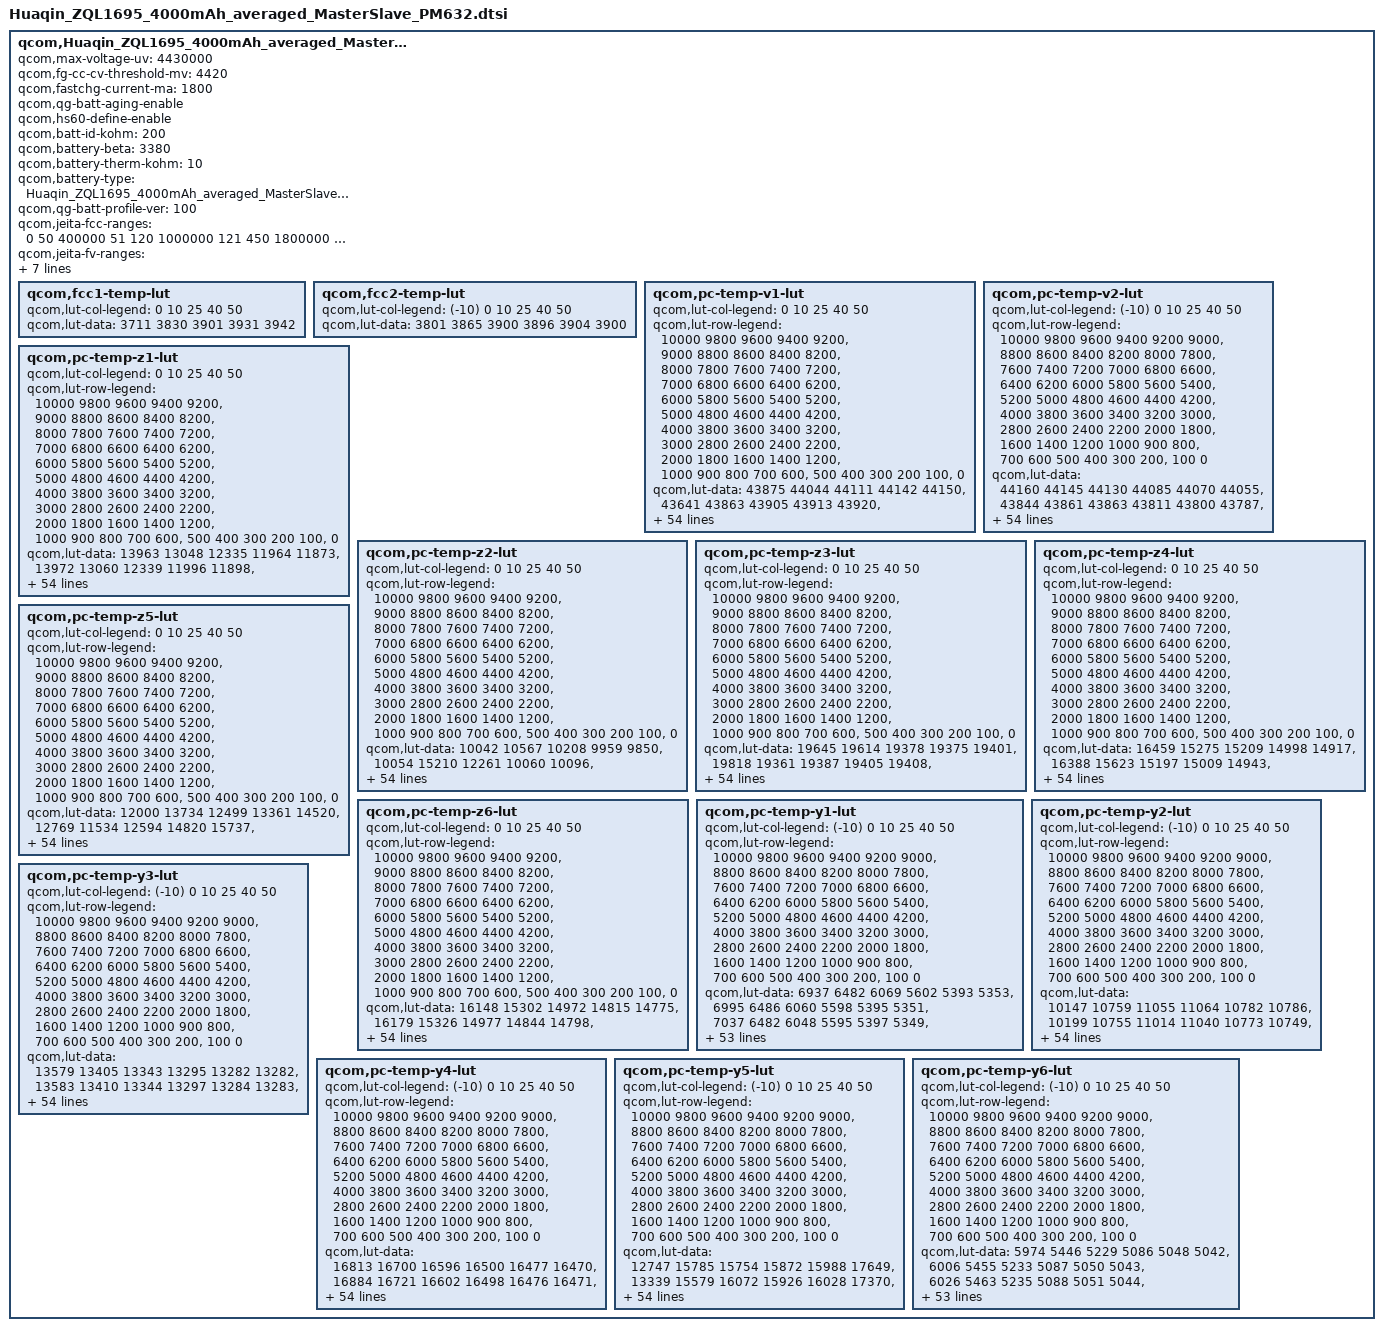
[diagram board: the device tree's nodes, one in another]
qcom,Huaqin_ZQL1695_4000mAh_averaged_MasterSlave_PM632 {
        /* Huaqin_ZQL1695_4000mAh_averaged_MasterSlave_PM632 */
	qcom,max-voltage-uv = <4430000>;
	qcom,fg-cc-cv-threshold-mv = <4420>;
	/* HS60 add for ZQL1693-60 Encrease FCC to 1800mA to trigger TA(5V/1.55A) more ICL by gaochao at 2019/11/05 start */
	qcom,fastchg-current-ma = <1800>;
	/* HS60 add for ZQL1693-60 Encrease FCC to 1800mA to trigger TA(5V/1.55A) more ICL by gaochao at 2019/11/05 end */
	/* HS60 add for SR-ZQL1695-01-357 Import battery aging by gaochao at 2019/08/29 start */
	qcom,qg-batt-aging-enable;
	/* HS60 add for SR-ZQL1695-01-357 Import battery aging by gaochao at 2019/08/29 end */
	/* HS70 add for HS70-135 Distinguish HS60 and HS70 charging by gaochao at 2019/10/03 start */
	qcom,hs60-define-enable;
	/* HS70 add for HS70-135 Distinguish HS60 and HS70 charging by gaochao at 2019/10/03 end */
	qcom,batt-id-kohm = <200>;
	qcom,battery-beta = <3380>;
	qcom,battery-therm-kohm = <10>;
	qcom,battery-type = "Huaqin_ZQL1695_4000mAh_averaged_MasterSlave_PM632";
	qcom,qg-batt-profile-ver = <100>;
	/*HS60 add for ZQL1693-50 by wangzikang at 2019/09/26 start*/
	/*HS60 add for ZQL1693-58 by wangzikang at 2019/10/18 start*/
	/* HS60 add for ZQL1693-60 Encrease FCC to 1800mA to trigger TA(5V/1.55A) more ICL by gaochao at 2019/11/05 start */
	qcom,jeita-fcc-ranges = <0   50  400000
				 51   120   1000000
				 121 450  1800000
				 451 500  1800000>;
	/* HS60 add for ZQL1693-60 Encrease FCC to 1800mA to trigger TA(5V/1.55A) more ICL by gaochao at 2019/11/05 end */
	/*HS60 add for ZQL1693-58 by wangzikang at 2019/10/18 end*/
	qcom,jeita-fv-ranges =  <0   50  4430000
				 51   120  4430000
				 121 450  4430000
				 451 500  4200000>;
	/*HS60 add for ZQL1693-50 by wangzikang at 2019/09/26 end*/
	/* HS60 add for SR-ZQL1695-01-357 Import battery aging by gaochao at 2019/08/29 start */
	qcom,vfloat-ranges = <0 299 4430000
	                      300 399 4410000
                              400 699 4390000
                              700 999 4370000
                              1000 9999 4320000>;

	qcom,vbat-rechg-ranges = <0 299 4360000
                                  300 399 4340000
                                  400 699 4320000
                                  700 999 4300000
                                  1000 9999 4250000>;
	/* HS60 add for SR-ZQL1695-01-357 Import battery aging by gaochao at 2019/08/29 end */

	/* COOL = 15 DegC, WARM = 45 DegC */
	qcom,jeita-soft-thresholds = <0x2554 0xFDC>;
	/* COLD = 0 DegC, HOT = 55 DegC */
	/*HS60 add for ZQL1693-50 by wangzikang at 2019/09/26 start*/
	qcom,jeita-hard-thresholds = <0x36B9 0xDBF>;//0xBEF -->0xDBF
	/*HS60 add for ZQL1693-50 by wangzikang at 2019/09/26 end*/

	qcom,fcc1-temp-lut {
		qcom,lut-col-legend = <0 10 25 40 50>;
		qcom,lut-data = <3711 3830 3901 3931 3942>;
	};

	qcom,fcc2-temp-lut {
		qcom,lut-col-legend = <(-10) 0 10 25 40 50>;
		qcom,lut-data = <3801 3865 3900 3896 3904 3900>;
	};

	qcom,pc-temp-v1-lut {
		qcom,lut-col-legend = <0 10 25 40 50>;
		qcom,lut-row-legend = <10000 9800 9600 9400 9200>,
			<9000 8800 8600 8400 8200>,
			<8000 7800 7600 7400 7200>,
			<7000 6800 6600 6400 6200>,
			<6000 5800 5600 5400 5200>,
			<5000 4800 4600 4400 4200>,
			<4000 3800 3600 3400 3200>,
			<3000 2800 2600 2400 2200>,
			<2000 1800 1600 1400 1200>,
			<1000 900 800 700 600>,
			<500 400 300 200 100>,
			<0>;
		qcom,lut-data = <43875 44044 44111 44142 44150>,
			<43641 43863 43905 43913 43920>,
			<43407 43622 43688 43690 43696>,
			<43170 43371 43463 43478 43481>,
			<42933 43130 43231 43263 43266>,
			<42694 42887 42986 43029 43038>,
			<42453 42645 42736 42782 42800>,
			<42217 42402 42490 42537 42560>,
			<41986 42161 42247 42296 42321>,
			<41758 41925 42006 42057 42081>,
			<41535 41694 41769 41823 41845>,
			<41317 41468 41536 41593 41609>,
			<41103 41247 41312 41368 41380>,
			<40896 41033 41096 41141 41159>,
			<40692 40824 40885 40921 40944>,
			<40496 40620 40681 40715 40735>,
			<40304 40425 40482 40519 40531>,
			<40120 40244 40293 40330 40336>,
			<39949 40073 40114 40151 40156>,
			<39793 39901 39937 39973 39981>,
			<39642 39734 39760 39778 39792>,
			<39490 39560 39583 39562 39579>,
			<39338 39357 39387 39351 39370>,
			<39189 39125 39126 39150 39174>,
			<39038 38928 38882 38963 38990>,
			<38890 38773 38751 38824 38849>,
			<38757 38643 38669 38722 38743>,
			<38633 38545 38594 38631 38648>,
			<38525 38470 38514 38540 38548>,
			<38444 38405 38437 38453 38448>,
			<38381 38345 38366 38370 38360>,
			<38328 38291 38298 38290 38281>,
			<38282 38241 38236 38217 38208>,
			<38241 38196 38178 38153 38142>,
			<38205 38155 38124 38096 38082>,
			<38173 38117 38075 38040 38020>,
			<38141 38083 38034 37986 37955>,
			<38100 38041 37988 37928 37885>,
			<38046 37975 37919 37850 37799>,
			<37978 37890 37829 37752 37696>,
			<37885 37794 37729 37647 37586>,
			<37762 37679 37617 37540 37473>,
			<37629 37543 37487 37416 37345>,
			<37484 37376 37326 37255 37185>,
			<37340 37234 37183 37121 37056>,
			<37218 37134 37084 37032 36976>,
			<37176 37104 37056 37006 36947>,
			<37140 37084 37038 36986 36929>,
			<37108 37056 37018 36966 36904>,
			<37071 37006 36963 36903 36831>,
			<36976 36805 36729 36636 36541>,
			<36673 36351 36286 36192 36096>,
			<36157 35753 35711 35621 35522>,
			<35466 34909 34927 34837 34736>,
			<34253 33521 33681 33613 33509>,
			<30000 30000 30000 30000 30000>;
	};

	qcom,pc-temp-v2-lut {
		qcom,lut-col-legend = <(-10) 0 10 25 40 50>;
		qcom,lut-row-legend = <10000 9800 9600 9400 9200 9000>,
			<8800 8600 8400 8200 8000 7800>,
			<7600 7400 7200 7000 6800 6600>,
			<6400 6200 6000 5800 5600 5400>,
			<5200 5000 4800 4600 4400 4200>,
			<4000 3800 3600 3400 3200 3000>,
			<2800 2600 2400 2200 2000 1800>,
			<1600 1400 1200 1000 900 800>,
			<700 600 500 400 300 200>,
			<100 0>;
		qcom,lut-data = <44160 44145 44130 44085 44070 44055>,
			<43844 43861 43863 43811 43800 43787>,
			<43551 43592 43605 43549 43541 43529>,
			<43286 43338 43358 43300 43295 43285>,
			<43051 43102 43125 43066 43064 43056>,
			<42823 42869 42892 42834 42834 42827>,
			<42577 42627 42650 42593 42596 42590>,
			<42323 42384 42404 42350 42354 42350>,
			<42081 42143 42161 42108 42115 42111>,
			<41867 41905 41921 41868 41878 41873>,
			<41657 41672 41685 41632 41644 41639>,
			<41415 41447 41454 41401 41414 41411>,
			<41132 41229 41228 41176 41188 41187>,
			<40865 41004 41009 40958 40967 40969>,
			<40659 40765 40799 40744 40752 40754>,
			<40477 40520 40589 40537 40544 40546>,
			<40268 40271 40363 40342 40345 40349>,
			<39993 40014 40119 40157 40155 40160>,
			<39712 39776 39883 39968 39969 39975>,
			<39494 39573 39656 39769 39793 39798>,
			<39312 39390 39439 39564 39617 39622>,
			<39141 39213 39243 39351 39410 39416>,
			<38971 39041 39063 39120 39162 39173>,
			<38806 38878 38900 38915 38944 38956>,
			<38637 38728 38752 38759 38786 38797>,
			<38451 38588 38619 38629 38654 38663>,
			<38289 38457 38497 38511 38537 38545>,
			<38189 38335 38385 38405 38432 38441>,
			<38115 38221 38283 38309 38338 38346>,
			<38051 38111 38190 38219 38250 38255>,
			<37994 38002 38104 38136 38170 38171>,
			<37942 37919 38019 38061 38095 38095>,
			<37888 37870 37927 37995 38026 38028>,
			<37832 37833 37845 37932 37958 37961>,
			<37776 37794 37789 37871 37884 37881>,
			<37716 37754 37746 37811 37807 37790>,
			<37652 37711 37704 37746 37724 37693>,
			<37584 37663 37660 37669 37631 37586>,
			<37509 37606 37611 37585 37534 37477>,
			<37431 37536 37545 37500 37443 37381>,
			<37356 37439 37453 37416 37358 37299>,
			<37280 37324 37345 37321 37262 37208>,
			<37205 37203 37214 37197 37132 37075>,
			<37135 37071 37073 37065 37003 36942>,
			<37062 36953 36938 36951 36904 36849>,
			<36976 36848 36840 36888 36853 36800>,
			<36929 36802 36807 36873 36841 36788>,
			<36878 36758 36772 36853 36826 36773>,
			<36823 36709 36721 36823 36796 36740>,
			<36757 36649 36606 36744 36695 36612>,
			<36665 36520 36330 36475 36374 36271>,
			<36526 36186 35834 35985 35879 35769>,
			<36263 35562 35147 35363 35234 35117>,
			<35772 34646 34163 34538 34379 34256>,
			<35039 33269 32681 33272 33150 32978>,
			<33863 31461 28043 28061 28166 28089>;
	};

	qcom,pc-temp-z1-lut {
		qcom,lut-col-legend = <0 10 25 40 50>;
		qcom,lut-row-legend = <10000 9800 9600 9400 9200>,
			<9000 8800 8600 8400 8200>,
			<8000 7800 7600 7400 7200>,
			<7000 6800 6600 6400 6200>,
			<6000 5800 5600 5400 5200>,
			<5000 4800 4600 4400 4200>,
			<4000 3800 3600 3400 3200>,
			<3000 2800 2600 2400 2200>,
			<2000 1800 1600 1400 1200>,
			<1000 900 800 700 600>,
			<500 400 300 200 100>,
			<0>;
		qcom,lut-data = <13963 13048 12335 11964 11873>,
			<13972 13060 12339 11996 11898>,
			<13968 13055 12335 12006 11908>,
			<13959 13048 12330 12003 11909>,
			<13951 13038 12323 11999 11910>,
			<13940 13024 12315 11997 11910>,
			<13916 13008 12306 11994 11911>,
			<13902 12987 12299 11993 11912>,
			<13899 12968 12293 11993 11913>,
			<13896 12959 12289 11994 11916>,
			<13888 12953 12287 11994 11917>,
			<13862 12949 12286 11996 11918>,
			<13832 12947 12285 11998 11919>,
			<13813 12946 12286 11998 11920>,
			<13797 12941 12287 11998 11921>,
			<13784 12928 12288 11999 11923>,
			<13772 12919 12289 12000 11924>,
			<13762 12922 12290 12002 11926>,
			<13761 12929 12291 12004 11928>,
			<13780 12931 12293 12005 11930>,
			<13800 12930 12295 12007 11932>,
			<13799 12929 12299 12008 11934>,
			<13787 12932 12302 12009 11935>,
			<13778 12941 12306 12011 11937>,
			<13776 12949 12310 12012 11938>,
			<13773 12956 12313 12015 11940>,
			<13774 12963 12317 12019 11943>,
			<13784 12969 12321 12023 11946>,
			<13796 12979 12326 12027 11949>,
			<13800 12985 12332 12031 11953>,
			<13798 12986 12338 12035 11957>,
			<13799 12987 12343 12039 11961>,
			<13812 12988 12348 12043 11965>,
			<13835 12992 12355 12048 11970>,
			<13848 12997 12363 12052 11974>,
			<13852 13004 12370 12057 11977>,
			<13856 13015 12377 12060 11979>,
			<13863 13027 12384 12064 11981>,
			<13878 13037 12391 12068 11984>,
			<13895 13048 12398 12071 11987>,
			<13914 13061 12406 12075 11990>,
			<13933 13078 12412 12080 11993>,
			<13939 13090 12419 12084 11996>,
			<13942 13098 12428 12086 11998>,
			<13983 13122 12439 12091 12002>,
			<14001 13110 12445 12092 12001>,
			<13953 13114 12447 12092 12000>,
			<13955 13108 12447 12092 12001>,
			<13986 13105 12451 12093 12003>,
			<14006 13123 12457 12096 12003>,
			<14014 13132 12469 12102 12009>,
			<14022 13163 12476 12109 12016>,
			<14018 13177 12494 12120 12027>,
			<14053 13221 12525 12140 12043>,
			<14053 13221 12525 12140 12043>,
			<14053 13221 12525 12140 12043>;
	};

	qcom,pc-temp-z2-lut {
		qcom,lut-col-legend = <0 10 25 40 50>;
		qcom,lut-row-legend = <10000 9800 9600 9400 9200>,
			<9000 8800 8600 8400 8200>,
			<8000 7800 7600 7400 7200>,
			<7000 6800 6600 6400 6200>,
			<6000 5800 5600 5400 5200>,
			<5000 4800 4600 4400 4200>,
			<4000 3800 3600 3400 3200>,
			<3000 2800 2600 2400 2200>,
			<2000 1800 1600 1400 1200>,
			<1000 900 800 700 600>,
			<500 400 300 200 100>,
			<0>;
		qcom,lut-data = <10042 10567 10208 9959 9850>,
			<10054 15210 12261 10060 10096>,
			<10057 12240 12300 10290 10183>,
			<10056 10197 11657 10893 10160>,
			<10055 10141 11061 11410 10127>,
			<10061 10119 10594 11189 10118>,
			<10074 10104 10241 10487 10123>,
			<10080 10089 10170 10148 10122>,
			<10079 10081 10156 10101 10093>,
			<10077 10081 10151 10078 10060>,
			<10074 10084 10152 10254 10057>,
			<10071 10088 10158 10829 10068>,
			<10067 10096 10201 11111 10076>,
			<10060 10107 10466 10696 10029>,
			<10047 10120 10717 10163 9955>,
			<10040 10134 10798 10233 9941>,
			<10051 10158 10849 10857 9953>,
			<10071 10253 10840 11230 9967>,
			<10078 10402 10556 10815 9978>,
			<10078 10442 10273 10199 9991>,
			<10077 10343 10263 10108 10027>,
			<10079 10244 10298 10273 10162>,
			<10082 10248 10326 10387 10265>,
			<10087 10289 10345 10284 10210>,
			<10097 10311 10357 10104 10091>,
			<10111 10304 10344 10063 10057>,
			<10123 10293 10288 10107 10096>,
			<10134 10286 10256 10162 10157>,
			<10143 10279 10288 10217 10240>,
			<10147 10275 10339 10276 10341>,
			<10149 10278 10363 10300 10366>,
			<10152 10285 10376 10310 10248>,
			<10157 10289 10382 10309 10108>,
			<10165 10296 10374 10272 10045>,
			<10174 10303 10358 10203 9999>,
			<10182 10306 10354 10177 9987>,
			<10191 10309 10358 10190 10038>,
			<10202 10313 10364 10214 10110>,
			<10216 10324 10385 10270 10156>,
			<10232 10340 10426 10377 10193>,
			<10246 10351 10451 10421 10219>,
			<10261 10359 10462 10358 10248>,
			<10302 10369 10466 10314 10261>,
			<10369 10385 10464 10349 10230>,
			<10404 10560 10523 10328 10238>,
			<10339 10619 10535 10313 10197>,
			<10339 10709 10519 10281 10201>,
			<10312 10949 10509 10266 10211>,
			<10270 11056 10509 10308 10229>,
			<10247 11188 10523 10389 10312>,
			<10221 11002 10610 10320 10211>,
			<10163 10822 10563 10148 9978>,
			<9964 10611 10500 10084 9933>,
			<9817 10392 10522 10014 9866>,
			<9817 10392 10522 10014 9866>,
			<9817 10392 10522 10014 9866>;
	};

	qcom,pc-temp-z3-lut {
		qcom,lut-col-legend = <0 10 25 40 50>;
		qcom,lut-row-legend = <10000 9800 9600 9400 9200>,
			<9000 8800 8600 8400 8200>,
			<8000 7800 7600 7400 7200>,
			<7000 6800 6600 6400 6200>,
			<6000 5800 5600 5400 5200>,
			<5000 4800 4600 4400 4200>,
			<4000 3800 3600 3400 3200>,
			<3000 2800 2600 2400 2200>,
			<2000 1800 1600 1400 1200>,
			<1000 900 800 700 600>,
			<500 400 300 200 100>,
			<0>;
		qcom,lut-data = <19645 19614 19378 19375 19401>,
			<19818 19361 19387 19405 19408>,
			<19873 19535 19422 19431 19415>,
			<19888 19665 19493 19457 19423>,
			<19895 19688 19531 19476 19432>,
			<19886 19701 19534 19480 19441>,
			<19859 19704 19535 19479 19452>,
			<19836 19699 19535 19477 19456>,
			<19818 19692 19534 19473 19456>,
			<19804 19684 19531 19470 19454>,
			<19801 19669 19523 19474 19451>,
			<19803 19657 19512 19488 19444>,
			<19807 19649 19512 19494 19437>,
			<19814 19641 19530 19467 19427>,
			<19831 19631 19545 19433 19417>,
			<19840 19616 19543 19431 19411>,
			<19830 19608 19534 19443 19407>,
			<19813 19619 19521 19450 19403>,
			<19808 19641 19487 19431 19397>,
			<19818 19647 19459 19401 19391>,
			<19829 19618 19459 19398 19390>,
			<19833 19590 19466 19413 19392>,
			<19835 19598 19472 19424 19395>,
			<19838 19632 19478 19413 19386>,
			<19843 19650 19482 19391 19365>,
			<19850 19647 19478 19377 19354>,
			<19853 19641 19458 19368 19349>,
			<19854 19633 19444 19363 19346>,
			<19853 19623 19439 19368 19368>,
			<19851 19614 19435 19380 19420>,
			<19840 19607 19436 19393 19438>,
			<19828 19601 19446 19416 19432>,
			<19818 19598 19457 19433 19423>,
			<19809 19597 19464 19430 19411>,
			<19799 19596 19469 19418 19395>,
			<19789 19594 19469 19407 19384>,
			<19779 19590 19461 19397 19376>,
			<19769 19586 19451 19389 19371>,
			<19758 19582 19448 19388 19368>,
			<19746 19578 19446 19387 19364>,
			<19733 19570 19443 19386 19363>,
			<19718 19557 19436 19383 19371>,
			<19694 19546 19429 19380 19377>,
			<19643 19539 19423 19381 19378>,
			<19346 19485 19407 19375 19374>,
			<19334 19466 19403 19367 19359>,
			<19322 19423 19401 19360 19356>,
			<19316 19323 19386 19355 19341>,
			<19313 19309 19368 19345 19338>,
			<19310 19304 19367 19340 19333>,
			<19309 19321 19374 19355 19362>,
			<19320 19335 19363 19386 19385>,
			<19340 19398 19372 19373 19380>,
			<19376 19494 19347 19376 19379>,
			<19376 19494 19347 19376 19379>,
			<19376 19494 19347 19376 19379>;
	};

	qcom,pc-temp-z4-lut {
		qcom,lut-col-legend = <0 10 25 40 50>;
		qcom,lut-row-legend = <10000 9800 9600 9400 9200>,
			<9000 8800 8600 8400 8200>,
			<8000 7800 7600 7400 7200>,
			<7000 6800 6600 6400 6200>,
			<6000 5800 5600 5400 5200>,
			<5000 4800 4600 4400 4200>,
			<4000 3800 3600 3400 3200>,
			<3000 2800 2600 2400 2200>,
			<2000 1800 1600 1400 1200>,
			<1000 900 800 700 600>,
			<500 400 300 200 100>,
			<0>;
		qcom,lut-data = <16459 15275 15209 14998 14917>,
			<16388 15623 15197 15009 14943>,
			<16272 15515 15154 15004 14948>,
			<16082 15392 15056 14937 14927>,
			<15894 15289 14984 14864 14891>,
			<15769 15189 14955 14847 14862>,
			<15666 15114 14933 14840 14834>,
			<15578 15055 14905 14830 14808>,
			<15503 15009 14872 14813 14785>,
			<15435 14974 14842 14789 14765>,
			<15370 14947 14820 14752 14752>,
			<15306 14921 14800 14699 14743>,
			<15245 14893 14770 14676 14737>,
			<15185 14866 14722 14700 14734>,
			<15125 14850 14685 14731 14731>,
			<15081 14841 14674 14725 14727>,
			<15057 14829 14667 14681 14719>,
			<15038 14791 14668 14655 14711>,
			<15008 14737 14697 14669 14706>,
			<14947 14722 14728 14696 14701>,
			<14890 14745 14733 14717 14703>,
			<14868 14776 14735 14734 14729>,
			<14855 14797 14740 14758 14766>,
			<14850 14816 14809 14813 14817>,
			<14853 14833 14889 14881 14875>,
			<14860 14854 14899 14896 14890>,
			<14868 14872 14894 14891 14882>,
			<14881 14874 14886 14881 14866>,
			<14893 14867 14875 14862 14825>,
			<14894 14858 14858 14829 14753>,
			<14891 14848 14838 14795 14719>,
			<14886 14835 14810 14752 14710>,
			<14879 14822 14784 14720 14705>,
			<14868 14807 14762 14713 14703>,
			<14856 14793 14744 14710 14703>,
			<14846 14781 14736 14710 14702>,
			<14834 14769 14733 14711 14703>,
			<14820 14762 14731 14713 14706>,
			<14802 14758 14735 14721 14714>,
			<14786 14755 14745 14736 14734>,
			<14778 14750 14749 14742 14744>,
			<14772 14744 14746 14740 14730>,
			<14768 14735 14742 14737 14720>,
			<14765 14723 14738 14736 14724>,
			<14964 14703 14711 14715 14708>,
			<14975 14697 14693 14704 14700>,
			<14982 14737 14685 14699 14693>,
			<14982 14839 14680 14684 14686>,
			<14981 14846 14680 14668 14661>,
			<14977 14846 14673 14662 14653>,
			<14969 14833 14693 14693 14681>,
			<14970 14838 14725 14682 14679>,
			<14989 14783 14720 14699 14687>,
			<14989 14715 14754 14699 14689>,
			<14989 14715 14754 14699 14689>,
			<14989 14715 14754 14699 14689>;
	};

	qcom,pc-temp-z5-lut {
		qcom,lut-col-legend = <0 10 25 40 50>;
		qcom,lut-row-legend = <10000 9800 9600 9400 9200>,
			<9000 8800 8600 8400 8200>,
			<8000 7800 7600 7400 7200>,
			<7000 6800 6600 6400 6200>,
			<6000 5800 5600 5400 5200>,
			<5000 4800 4600 4400 4200>,
			<4000 3800 3600 3400 3200>,
			<3000 2800 2600 2400 2200>,
			<2000 1800 1600 1400 1200>,
			<1000 900 800 700 600>,
			<500 400 300 200 100>,
			<0>;
		qcom,lut-data = <12000 13734 12499 13361 14520>,
			<12769 11534 12594 14820 15737>,
			<13089 13016 13067 15833 16570>,
			<13232 14305 14275 16645 17012>,
			<13314 14816 15294 17290 17401>,
			<13358 15176 15885 17851 18115>,
			<13388 15455 16363 18561 19285>,
			<13408 15744 16793 18907 20324>,
			<13433 15953 17172 19122 21065>,
			<13473 16025 17577 19491 21714>,
			<13538 16105 17976 21705 22321>,
			<13731 16252 18468 27483 23002>,
			<14024 16663 19776 30218 23338>,
			<14467 17226 24245 26267 22793>,
			<15152 17649 28604 21198 21941>,
			<15588 17944 30738 21960 21931>,
			<15671 18392 32286 28273 23009>,
			<15727 20768 32293 32032 24144>,
			<15938 24618 27099 28280 24744>,
			<17383 25745 21945 22733 25261>,
			<19525 24394 22841 23077 26144>,
			<21511 23026 26880 30872 28241>,
			<23655 26869 30241 36319 29767>,
			<26016 39258 32719 31800 26839>,
			<29043 45752 34418 23116 20247>,
			<32326 42962 32922 18803 16772>,
			<34277 38051 26200 16626 15180>,
			<35431 34224 21274 15562 14382>,
			<36151 30736 19624 15597 16363>,
			<35899 28274 18607 15942 21334>,
			<34073 27097 18594 16780 24011>,
			<32138 26264 19603 20804 25080>,
			<31049 26074 21116 24576 25657>,
			<30175 26759 23981 25243 25181>,
			<29395 27755 27575 25554 23732>,
			<28590 28474 28567 25613 23056>,
			<27918 29138 28505 25302 23396>,
			<27705 29853 28413 24966 23807>,
			<28238 30971 28363 24917 23391>,
			<28777 32075 28293 24907 22064>,
			<28786 31770 28034 24802 21416>,
			<28556 28490 25737 22117 21590>,
			<27196 27508 23936 20308 21853>,
			<22852 29030 23300 20800 22256>,
			<12474 26111 24314 21122 22098>,
			<12122 23329 24931 19997 18658>,
			<11907 19222 24210 18757 18238>,
			<11787 12321 21061 18807 16649>,
			<11715 12044 17992 18949 18801>,
			<11690 11981 18626 19354 19920>,
			<11736 12417 18658 18044 20447>,
			<11864 12632 15117 19489 20392>,
			<11914 15684 15354 16091 17676>,
			<12655 24085 13345 15518 16090>,
			<12655 24085 13345 15518 16090>,
			<12655 24085 13345 15518 16090>;
	};

	qcom,pc-temp-z6-lut {
		qcom,lut-col-legend = <0 10 25 40 50>;
		qcom,lut-row-legend = <10000 9800 9600 9400 9200>,
			<9000 8800 8600 8400 8200>,
			<8000 7800 7600 7400 7200>,
			<7000 6800 6600 6400 6200>,
			<6000 5800 5600 5400 5200>,
			<5000 4800 4600 4400 4200>,
			<4000 3800 3600 3400 3200>,
			<3000 2800 2600 2400 2200>,
			<2000 1800 1600 1400 1200>,
			<1000 900 800 700 600>,
			<500 400 300 200 100>,
			<0>;
		qcom,lut-data = <16148 15302 14972 14815 14775>,
			<16179 15326 14977 14844 14798>,
			<16168 15346 14974 14850 14806>,
			<16083 15356 14966 14838 14801>,
			<15980 15333 14956 14822 14792>,
			<15907 15283 14944 14815 14785>,
			<15841 15243 14931 14810 14779>,
			<15785 15211 14916 14804 14773>,
			<15737 15183 14901 14794 14764>,
			<15695 15159 14885 14783 14754>,
			<15658 15137 14870 14772 14746>,
			<15624 15117 14856 14760 14739>,
			<15594 15099 14844 14751 14732>,
			<15569 15083 14835 14744 14725>,
			<15546 15069 14826 14739 14718>,
			<15524 15056 14819 14732 14712>,
			<15503 15045 14812 14724 14707>,
			<15483 15035 14806 14717 14701>,
			<15463 15026 14800 14711 14695>,
			<15440 15021 14796 14707 14690>,
			<15423 15018 14797 14709 14690>,
			<15419 15017 14802 14724 14704>,
			<15418 15025 14810 14743 14721>,
			<15417 15054 14844 14760 14736>,
			<15421 15074 14880 14777 14750>,
			<15431 15082 14882 14780 14753>,
			<15439 15087 14871 14774 14747>,
			<15448 15086 14860 14767 14740>,
			<15454 15080 14853 14760 14735>,
			<15454 15072 14846 14754 14732>,
			<15449 15065 14839 14748 14728>,
			<15442 15058 14834 14743 14722>,
			<15436 15052 14829 14738 14715>,
			<15429 15046 14824 14732 14708>,
			<15422 15041 14821 14726 14699>,
			<15416 15036 14817 14721 14694>,
			<15411 15031 14811 14717 14690>,
			<15404 15029 14807 14713 14688>,
			<15397 15028 14808 14715 14690>,
			<15391 15028 14813 14721 14696>,
			<15389 15026 14814 14724 14699>,
			<15387 15021 14811 14721 14698>,
			<15381 15015 14807 14719 14697>,
			<15365 15011 14803 14719 14699>,
			<15310 14981 14786 14708 14691>,
			<15310 14971 14777 14699 14679>,
			<15309 14965 14773 14693 14675>,
			<15306 14959 14763 14684 14664>,
			<15304 14957 14754 14671 14651>,
			<15304 14957 14752 14667 14645>,
			<15308 14964 14767 14689 14674>,
			<15327 14982 14779 14704 14688>,
			<15358 15001 14785 14707 14693>,
			<15398 15037 14794 14713 14697>,
			<15398 15037 14794 14713 14697>,
			<15398 15037 14794 14713 14697>;
	};

	qcom,pc-temp-y1-lut {
		qcom,lut-col-legend = <(-10) 0 10 25 40 50>;
		qcom,lut-row-legend = <10000 9800 9600 9400 9200 9000>,
			<8800 8600 8400 8200 8000 7800>,
			<7600 7400 7200 7000 6800 6600>,
			<6400 6200 6000 5800 5600 5400>,
			<5200 5000 4800 4600 4400 4200>,
			<4000 3800 3600 3400 3200 3000>,
			<2800 2600 2400 2200 2000 1800>,
			<1600 1400 1200 1000 900 800>,
			<700 600 500 400 300 200>,
			<100 0>;
		qcom,lut-data = <6937 6482 6069 5602 5393 5353>,
			<6995 6486 6060 5598 5395 5351>,
			<7037 6482 6048 5595 5397 5349>,
			<7065 6473 6034 5591 5398 5347>,
			<7082 6463 6022 5588 5398 5346>,
			<7088 6457 6015 5585 5398 5345>,
			<7080 6452 6013 5583 5398 5345>,
			<7056 6445 6012 5581 5397 5345>,
			<7044 6443 6010 5579 5397 5345>,
			<7050 6451 6005 5577 5396 5346>,
			<7059 6460 6001 5575 5396 5346>,
			<7060 6457 6000 5575 5395 5346>,
			<7051 6444 6000 5574 5395 5347>,
			<7043 6438 5999 5574 5394 5347>,
			<7046 6447 5993 5574 5395 5347>,
			<7051 6460 5987 5574 5396 5348>,
			<7053 6461 5988 5574 5397 5349>,
			<7060 6453 5993 5575 5397 5350>,
			<7068 6447 5997 5576 5398 5351>,
			<7068 6453 5997 5578 5399 5352>,
			<7067 6466 5999 5582 5400 5353>,
			<7066 6473 6000 5585 5402 5355>,
			<7057 6472 6001 5588 5404 5355>,
			<7042 6469 6001 5591 5406 5356>,
			<7037 6466 6002 5594 5407 5358>,
			<7039 6459 6005 5596 5409 5359>,
			<7043 6457 6008 5600 5411 5361>,
			<7056 6458 6012 5605 5414 5364>,
			<7084 6459 6017 5610 5417 5366>,
			<7097 6460 6019 5615 5420 5368>,
			<7071 6462 6021 5620 5423 5370>,
			<7032 6465 6022 5625 5426 5372>,
			<7024 6467 6024 5629 5428 5375>,
			<7035 6467 6027 5634 5431 5377>,
			<7044 6469 6028 5639 5433 5378>,
			<7049 6480 6029 5644 5435 5379>,
			<7060 6488 6031 5647 5437 5379>,
			<7069 6486 6041 5647 5438 5381>,
			<7077 6478 6054 5648 5438 5384>,
			<7082 6475 6061 5649 5439 5385>,
			<7077 6478 6069 5651 5441 5385>,
			<7055 6482 6073 5655 5443 5385>,
			<7035 6480 6079 5659 5445 5387>,
			<7036 6471 6085 5666 5447 5389>,
			<7043 6475 6101 5678 5451 5393>,
			<7034 6489 6115 5687 5453 5395>,
			<7030 6494 6118 5692 5453 5395>,
			<7034 6498 6125 5689 5455 5396>,
			<7066 6516 6111 5686 5454 5395>,
			<7121 6520 6115 5685 5453 5398>,
			<7179 6554 6110 5689 5459 5399>,
			<7235 6628 6151 5706 5464 5406>,
			<7397 6744 6230 5728 5472 5413>,
			<7517 6949 6329 5758 5486 5423>,
			<7517 6949 6329 5758 5486 5423>,
			<7517 6949 6329 5758 5486 5423>;
	};

	qcom,pc-temp-y2-lut {
		qcom,lut-col-legend = <(-10) 0 10 25 40 50>;
		qcom,lut-row-legend = <10000 9800 9600 9400 9200 9000>,
			<8800 8600 8400 8200 8000 7800>,
			<7600 7400 7200 7000 6800 6600>,
			<6400 6200 6000 5800 5600 5400>,
			<5200 5000 4800 4600 4400 4200>,
			<4000 3800 3600 3400 3200 3000>,
			<2800 2600 2400 2200 2000 1800>,
			<1600 1400 1200 1000 900 800>,
			<700 600 500 400 300 200>,
			<100 0>;
		qcom,lut-data = <10147 10759 11055 11064 10782 10786>,
			<10199 10755 11014 11040 10773 10749>,
			<10256 10750 10970 11008 10757 10706>,
			<10311 10746 10928 10974 10738 10663>,
			<10359 10742 10892 10943 10717 10627>,
			<10394 10739 10866 10919 10697 10603>,
			<10412 10737 10848 10901 10673 10591>,
			<10423 10732 10834 10883 10647 10582>,
			<10437 10732 10831 10877 10642 10572>,
			<10460 10741 10835 10877 10671 10557>,
			<10490 10752 10841 10879 10703 10546>,
			<10540 10752 10846 10889 10712 10553>,
			<10641 10751 10853 10913 10716 10573>,
			<10711 10750 10864 10938 10723 10586>,
			<10698 10814 10890 10966 10742 10603>,
			<10664 10905 10923 10993 10770 10627>,
			<10653 10922 10950 11014 10801 10655>,
			<10694 10911 10975 11036 10840 10695>,
			<10749 10902 10996 11063 10893 10745>,
			<10777 10912 11009 11120 11008 10864>,
			<10797 10933 11021 11182 11129 11001>,
			<10806 10946 11035 11185 11123 11012>,
			<10798 10955 11052 11135 10984 10922>,
			<10773 10961 11068 11098 10889 10851>,
			<10695 10963 11080 11117 10906 10843>,
			<10233 10964 11091 11159 10946 10843>,
			<9782 10964 11095 11183 10986 10861>,
			<9716 10953 11094 11198 11035 10967>,
			<9697 10941 11094 11209 11081 11059>,
			<9687 10947 11095 11220 11117 11052>,
			<9682 10984 11099 11241 11151 11028>,
			<9678 11009 11098 11255 11182 11024>,
			<9674 10981 11093 11260 11235 11136>,
			<9670 10920 11086 11263 11281 11276>,
			<9667 10873 11076 11264 11275 11327>,
			<9666 10838 11060 11258 11236 11353>,
			<9664 10801 11041 11249 11195 11338>,
			<9663 10753 11020 11225 11112 11173>,
			<9662 10692 10993 11192 11031 10981>,
			<9661 10582 10958 11171 11026 10956>,
			<9661 10173 10906 11157 11046 10973>,
			<9661 9748 10843 11139 11059 10983>,
			<9660 9680 10771 11109 11028 10928>,
			<9660 9669 10683 11064 10962 10819>,
			<9659 9663 10569 10976 10799 10673>,
			<9658 9659 10431 10917 10744 10605>,
			<9657 9658 10363 10904 10752 10605>,
			<9656 9657 10350 10927 10811 10688>,
			<9655 9656 10296 10973 10853 10755>,
			<9653 9655 9863 10982 10848 10655>,
			<9651 9653 9676 10956 10809 10593>,
			<9649 9650 9657 10896 10724 10567>,
			<9648 9648 9651 10816 10608 10468>,
			<9647 9647 9650 10730 10550 10359>,
			<9647 9647 9650 10730 10550 10359>,
			<9647 9647 9650 10730 10550 10359>;
	};

	qcom,pc-temp-y3-lut {
		qcom,lut-col-legend = <(-10) 0 10 25 40 50>;
		qcom,lut-row-legend = <10000 9800 9600 9400 9200 9000>,
			<8800 8600 8400 8200 8000 7800>,
			<7600 7400 7200 7000 6800 6600>,
			<6400 6200 6000 5800 5600 5400>,
			<5200 5000 4800 4600 4400 4200>,
			<4000 3800 3600 3400 3200 3000>,
			<2800 2600 2400 2200 2000 1800>,
			<1600 1400 1200 1000 900 800>,
			<700 600 500 400 300 200>,
			<100 0>;
		qcom,lut-data = <13579 13405 13343 13295 13282 13282>,
			<13583 13410 13344 13297 13284 13283>,
			<13586 13414 13347 13300 13286 13284>,
			<13589 13419 13351 13302 13288 13285>,
			<13590 13423 13353 13304 13289 13286>,
			<13590 13425 13355 13306 13291 13287>,
			<13589 13426 13355 13307 13292 13289>,
			<13586 13425 13355 13309 13293 13290>,
			<13584 13426 13355 13310 13295 13291>,
			<13593 13426 13355 13310 13299 13292>,
			<13604 13428 13356 13311 13302 13293>,
			<13595 13433 13356 13313 13303 13295>,
			<13531 13447 13357 13316 13304 13298>,
			<13481 13454 13358 13317 13304 13300>,
			<13488 13436 13363 13316 13304 13301>,
			<13505 13408 13369 13314 13304 13301>,
			<13511 13400 13368 13313 13304 13302>,
			<13500 13398 13362 13313 13303 13304>,
			<13483 13397 13356 13313 13302 13305>,
			<13474 13395 13351 13314 13302 13304>,
			<13468 13392 13346 13316 13302 13301>,
			<13463 13389 13342 13315 13301 13298>,
			<13458 13386 13339 13309 13294 13291>,
			<13453 13383 13336 13303 13289 13286>,
			<13445 13380 13334 13300 13288 13285>,
			<13430 13377 13332 13298 13287 13285>,
			<13418 13375 13332 13297 13287 13285>,
			<13418 13374 13332 13298 13287 13287>,
			<13426 13373 13332 13298 13286 13288>,
			<13435 13368 13332 13298 13286 13287>,
			<13448 13350 13333 13298 13286 13284>,
			<13467 13339 13334 13298 13286 13283>,
			<13489 13345 13331 13298 13288 13285>,
			<13519 13357 13328 13299 13290 13287>,
			<13554 13366 13328 13300 13290 13287>,
			<13596 13372 13330 13302 13288 13288>,
			<13647 13377 13333 13304 13288 13288>,
			<13697 13382 13337 13302 13288 13286>,
			<13746 13387 13341 13301 13288 13283>,
			<13793 13395 13343 13301 13288 13284>,
			<13835 13415 13344 13301 13290 13287>,
			<13871 13443 13345 13301 13291 13289>,
			<13912 13476 13348 13300 13289 13287>,
			<13959 13520 13351 13298 13287 13284>,
			<14021 13603 13355 13300 13289 13287>,
			<14120 13754 13365 13308 13296 13293>,
			<14196 13861 13374 13316 13302 13298>,
			<14309 13958 13374 13316 13305 13300>,
			<14513 13997 13383 13319 13306 13302>,
			<14808 14202 13427 13321 13304 13296>,
			<15521 14663 13536 13315 13298 13293>,
			<17993 16735 13928 13313 13299 13296>,
			<25269 26117 15395 13324 13303 13301>,
			<59945 65535 24318 13339 13313 13310>,
			<59945 65535 24318 13339 13313 13310>,
			<59945 65535 24318 13339 13313 13310>;
	};

	qcom,pc-temp-y4-lut {
		qcom,lut-col-legend = <(-10) 0 10 25 40 50>;
		qcom,lut-row-legend = <10000 9800 9600 9400 9200 9000>,
			<8800 8600 8400 8200 8000 7800>,
			<7600 7400 7200 7000 6800 6600>,
			<6400 6200 6000 5800 5600 5400>,
			<5200 5000 4800 4600 4400 4200>,
			<4000 3800 3600 3400 3200 3000>,
			<2800 2600 2400 2200 2000 1800>,
			<1600 1400 1200 1000 900 800>,
			<700 600 500 400 300 200>,
			<100 0>;
		qcom,lut-data = <16813 16700 16596 16500 16477 16470>,
			<16884 16721 16602 16498 16476 16471>,
			<16980 16754 16609 16497 16475 16472>,
			<17080 16791 16615 16498 16476 16473>,
			<17161 16823 16621 16499 16477 16474>,
			<17204 16841 16626 16501 16478 16475>,
			<17202 16846 16630 16504 16481 16475>,
			<17187 16848 16634 16509 16484 16476>,
			<17170 16850 16640 16514 16485 16478>,
			<17147 16851 16648 16522 16485 16481>,
			<17127 16852 16657 16530 16485 16484>,
			<17134 16846 16669 16537 16487 16486>,
			<17199 16825 16683 16543 16495 16488>,
			<17251 16814 16694 16553 16503 16490>,
			<17233 16841 16703 16571 16513 16495>,
			<17178 16880 16710 16593 16524 16502>,
			<17113 16876 16706 16616 16538 16511>,
			<17016 16808 16686 16642 16557 16521>,
			<16923 16748 16663 16654 16574 16533>,
			<16885 16731 16638 16643 16592 16555>,
			<16867 16721 16612 16620 16605 16576>,
			<16848 16708 16593 16589 16596 16572>,
			<16812 16692 16579 16536 16537 16526>,
			<16773 16675 16570 16502 16493 16489>,
			<16763 16660 16565 16502 16487 16482>,
			<16771 16647 16562 16502 16483 16478>,
			<16781 16633 16562 16503 16484 16477>,
			<16790 16610 16561 16508 16491 16481>,
			<16799 16590 16561 16515 16502 16487>,
			<16803 16589 16560 16523 16514 16497>,
			<16803 16596 16558 16532 16526 16513>,
			<16803 16601 16554 16541 16534 16526>,
			<16803 16599 16542 16552 16540 16537>,
			<16804 16596 16531 16560 16544 16544>,
			<16805 16597 16532 16560 16543 16543>,
			<16805 16612 16542 16555 16541 16534>,
			<16805 16633 16553 16549 16538 16525>,
			<16807 16650 16568 16535 16521 16511>,
			<16811 16668 16585 16520 16503 16499>,
			<16817 16687 16598 16517 16501 16499>,
			<16821 16712 16610 16520 16504 16505>,
			<16829 16732 16615 16522 16505 16509>,
			<16840 16729 16613 16517 16491 16491>,
			<16854 16714 16610 16511 16476 16471>,
			<16873 16713 16610 16511 16477 16474>,
			<16906 16725 16623 16521 16495 16500>,
			<16922 16744 16644 16541 16524 16541>,
			<16927 16762 16644 16551 16542 16560>,
			<16929 16755 16664 16571 16570 16583>,
			<16925 16777 16727 16588 16570 16567>,
			<16960 16797 16744 16545 16497 16497>,
			<17395 17059 16758 16520 16482 16483>,
			<18785 19685 17056 16535 16488 16485>,
			<27573 55001 23531 16586 16525 16523>,
			<27573 55001 23531 16586 16525 16523>,
			<27573 55001 23531 16586 16525 16523>;
	};

	qcom,pc-temp-y5-lut {
		qcom,lut-col-legend = <(-10) 0 10 25 40 50>;
		qcom,lut-row-legend = <10000 9800 9600 9400 9200 9000>,
			<8800 8600 8400 8200 8000 7800>,
			<7600 7400 7200 7000 6800 6600>,
			<6400 6200 6000 5800 5600 5400>,
			<5200 5000 4800 4600 4400 4200>,
			<4000 3800 3600 3400 3200 3000>,
			<2800 2600 2400 2200 2000 1800>,
			<1600 1400 1200 1000 900 800>,
			<700 600 500 400 300 200>,
			<100 0>;
		qcom,lut-data = <12747 15785 15754 15872 15988 17649>,
			<13339 15579 16072 15926 16028 17370>,
			<13906 15439 16194 15901 16009 17081>,
			<14436 15350 16165 15816 15942 16797>,
			<14921 15300 16030 15688 15838 16533>,
			<15351 15276 15833 15534 15707 16303>,
			<15685 15264 15498 15336 15501 16114>,
			<15953 15278 15048 15073 15259 15937>,
			<16377 15350 14789 14781 15254 15727>,
			<17812 15533 14618 14356 16009 15415>,
			<19422 15850 14514 14043 16727 15192>,
			<19256 16759 14590 14075 16589 15431>,
			<16523 18759 14900 14219 16007 16113>,
			<14372 19786 15359 14276 15414 16397>,
			<16068 18479 16480 13998 14815 15957>,
			<19942 16611 17891 13664 14276 15393>,
			<21422 16358 19019 13745 13947 15196>,
			<20426 17158 20126 14414 13693 15085>,
			<19279 18079 20610 15453 13605 15044>,
			<19311 18754 20459 18474 14938 15415>,
			<20159 19376 20215 22146 16975 16119>,
			<20984 19845 20043 22701 17790 16758>,
			<21519 20251 19721 21399 18195 17533>,
			<21951 20583 19499 19863 18365 17970>,
			<21669 20829 19376 18517 17844 17535>,
			<17486 21121 19227 17270 16941 16699>,
			<13232 21437 19346 16966 16540 16418>,
			<12564 22251 19755 17136 15900 16453>,
			<12344 23124 20361 17332 15374 16477>,
			<12273 22189 21601 17432 15369 15958>,
			<12356 17201 23398 17534 15449 14794>,
			<12517 13857 23901 17705 15628 14381>,
			<12679 14622 22102 18232 16588 15202>,
			<12893 16186 20212 19071 17693 16453>,
			<13091 17199 20067 20409 18170 17592>,
			<13249 17858 20195 22541 18468 18824>,
			<13400 18321 20329 23555 18755 19309>,
			<13445 18592 20610 22516 19116 18480>,
			<13247 18796 20920 20741 19408 17399>,
			<13016 18793 20659 19533 19424 17480>,
			<12957 17199 19227 18599 19202 18617>,
			<12831 15120 18153 17899 19090 19348>,
			<12761 14295 17976 17206 18758 18987>,
			<12884 13865 17812 16580 18045 18205>,
			<13047 13642 17066 15952 16239 16686>,
			<13060 13522 16025 15850 15647 15091>,
			<13059 13467 15567 16201 15657 14599>,
			<13164 13427 15524 16244 16360 15062>,
			<13474 13509 15413 16880 16396 15353>,
			<13501 13901 14457 17066 15934 14463>,
			<12812 13876 13977 17088 16896 15487>,
			<11296 11696 13720 17520 17677 16553>,
			<9894 9554 12074 19640 17954 17612>,
			<9038 8905 9539 23092 23779 23111>,
			<9038 8905 9539 23092 23779 23111>,
			<9038 8905 9539 23092 23779 23111>;
	};

	qcom,pc-temp-y6-lut {
		qcom,lut-col-legend = <(-10) 0 10 25 40 50>;
		qcom,lut-row-legend = <10000 9800 9600 9400 9200 9000>,
			<8800 8600 8400 8200 8000 7800>,
			<7600 7400 7200 7000 6800 6600>,
			<6400 6200 6000 5800 5600 5400>,
			<5200 5000 4800 4600 4400 4200>,
			<4000 3800 3600 3400 3200 3000>,
			<2800 2600 2400 2200 2000 1800>,
			<1600 1400 1200 1000 900 800>,
			<700 600 500 400 300 200>,
			<100 0>;
		qcom,lut-data = <5974 5446 5229 5086 5048 5042>,
			<6006 5455 5233 5087 5050 5043>,
			<6026 5463 5235 5088 5051 5044>,
			<6037 5469 5236 5090 5053 5046>,
			<6042 5472 5237 5091 5055 5047>,
			<6043 5474 5237 5093 5056 5048>,
			<6038 5472 5237 5095 5058 5049>,
			<6020 5469 5235 5097 5059 5051>,
			<6008 5466 5235 5099 5061 5052>,
			<6003 5464 5236 5101 5063 5053>,
			<5999 5462 5237 5104 5066 5055>,
			<5990 5462 5239 5107 5068 5057>,
			<5967 5464 5242 5111 5071 5060>,
			<5950 5464 5245 5115 5073 5062>,
			<5947 5460 5251 5119 5076 5065>,
			<5946 5453 5255 5123 5079 5067>,
			<5942 5442 5253 5129 5083 5070>,
			<5912 5423 5244 5136 5087 5074>,
			<5879 5408 5233 5140 5092 5078>,
			<5870 5403 5222 5138 5096 5082>,
			<5867 5400 5212 5132 5100 5086>,
			<5864 5396 5204 5123 5096 5084>,
			<5860 5392 5198 5103 5074 5065>,
			<5856 5388 5194 5090 5058 5050>,
			<5850 5386 5193 5088 5056 5048>,
			<5840 5384 5192 5087 5054 5046>,
			<5833 5383 5192 5087 5054 5046>,
			<5836 5382 5193 5089 5056 5049>,
			<5853 5380 5194 5092 5060 5052>,
			<5874 5379 5196 5095 5063 5054>,
			<5897 5377 5198 5098 5066 5057>,
			<5925 5377 5199 5101 5070 5060>,
			<5958 5385 5196 5105 5073 5065>,
			<5999 5405 5192 5109 5075 5068>,
			<6044 5427 5194 5110 5075 5068>,
			<6091 5455 5200 5110 5074 5066>,
			<6141 5487 5209 5110 5072 5064>,
			<6188 5525 5220 5106 5068 5059>,
			<6232 5570 5233 5101 5063 5053>,
			<6274 5618 5246 5101 5063 5054>,
			<6310 5666 5259 5102 5065 5058>,
			<6340 5719 5275 5103 5066 5061>,
			<6375 5781 5293 5102 5061 5054>,
			<6420 5856 5316 5101 5056 5047>,
			<6482 5968 5349 5103 5058 5050>,
			<6584 6132 5411 5115 5069 5063>,
			<6663 6236 5452 5127 5082 5079>,
			<6775 6330 5451 5129 5089 5086>,
			<6965 6374 5496 5136 5098 5093>,
			<7239 6559 5607 5142 5096 5085>,
			<7881 6953 5788 5126 5071 5063>,
			<9963 8685 6224 5120 5069 5062>,
			<15663 16194 7551 5137 5074 5068>,
			<37883 65535 15917 5171 5094 5087>,
			<37883 65535 15917 5171 5094 5087>,
			<37883 65535 15917 5171 5094 5087>;
	};

};
